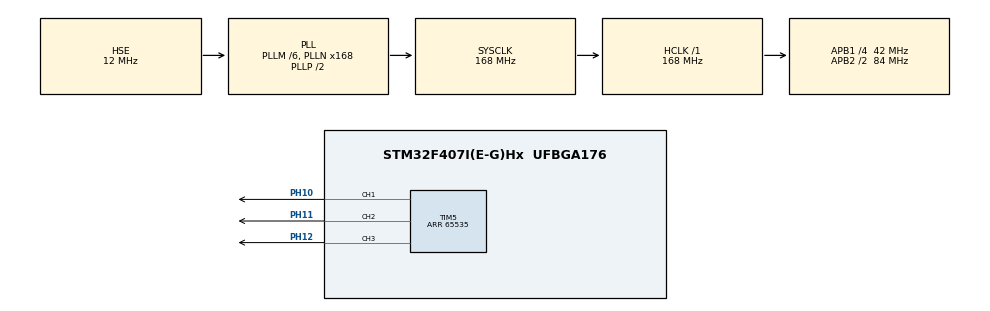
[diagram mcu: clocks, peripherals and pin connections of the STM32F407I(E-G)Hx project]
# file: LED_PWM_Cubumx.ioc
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Mcu.Family=STM32F4
Mcu.Name=STM32F407I(E-G)Hx
Mcu.Package=UFBGA176
NVIC.PriorityGroup=NVIC_PRIORITYGROUP_4
PA13.Mode=Serial_Wire
PA13.Signal=SYS_JTMS-SWDIO
PA14.Mode=Serial_Wire
PA14.Signal=SYS_JTCK-SWCLK
PH0-OSC_IN.Mode=HSE-External-Oscillator
PH0-OSC_IN.Signal=RCC_OSC_IN
PH1-OSC_OUT.Mode=HSE-External-Oscillator
PH1-OSC_OUT.Signal=RCC_OSC_OUT
PH10.Signal=S_TIM5_CH1
PH11.Signal=S_TIM5_CH2
PH12.Signal=S_TIM5_CH3
ProjectManager.HeapSize=0x200
ProjectManager.StackSize=0x400
ProjectManager.TargetToolchain=MDK-ARM V5.32
RCC.48MHZClocksFreq_Value=84000000
RCC.AHBFreq_Value=168000000
RCC.APB1CLKDivider=RCC_HCLK_DIV4
RCC.APB1Freq_Value=42000000
RCC.APB1TimFreq_Value=84000000
RCC.APB2CLKDivider=RCC_HCLK_DIV2
RCC.APB2Freq_Value=84000000
RCC.APB2TimFreq_Value=168000000
RCC.CortexFreq_Value=168000000
RCC.HCLKFreq_Value=168000000
RCC.HSE_VALUE=12000000
RCC.HSI_VALUE=16000000
RCC.LSE_VALUE=32768
RCC.PLLM=6
RCC.PLLN=168
RCC.PLLSourceVirtual=RCC_PLLSOURCE_HSE
RCC.SYSCLKFreq_VALUE=168000000
RCC.SYSCLKSource=RCC_SYSCLKSOURCE_PLLCLK
RCC.VCOOutputFreq_Value=336000000
SH.S_TIM5_CH1.0=TIM5_CH1,PWM Generation1 CH1
SH.S_TIM5_CH2.0=TIM5_CH2,PWM Generation2 CH2
SH.S_TIM5_CH3.0=TIM5_CH3,PWM Generation3 CH3
TIM5.Channel-PWM\ Generation1\ CH1=TIM_CHANNEL_1
TIM5.Channel-PWM\ Generation2\ CH2=TIM_CHANNEL_2
TIM5.Channel-PWM\ Generation3\ CH3=TIM_CHANNEL_3
TIM5.Period=65535
TIM5.Pulse-PWM\ Generation1\ CH1=10000
TIM5.Pulse-PWM\ Generation2\ CH2=10000
VP_TIM5_VS_ClockSourceINT.Mode=Internal
board=custom

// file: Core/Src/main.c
/* USER CODE BEGIN Header */
/**
  ******************************************************************************
  * @file           : main.c
  * @brief          : Main program body
  ******************************************************************************
  * @attention
  *
  * Copyright (c) 2025 STMicroelectronics.
  * All rights reserved.
  *
  * This software is licensed under terms that can be found in the LICENSE file
  * in the root directory of this software component.
  * If no LICENSE file comes with this software, it is provided AS-IS.
  *
  ******************************************************************************
  */
/* USER CODE END Header */
#include "main.h"
#include "tim.h"
#include "gpio.h"

void SystemClock_Config(void);

/* USER CODE BEGIN 0 */
	void aRGB_LED_SHOW(uint32_t aRGB);
/* USER CODE END 0 */

int main(void)
{

  /* USER CODE BEGIN 1 */
	uint32_t colors[] = {
    0xFFFF0000, // 红
    0xFFFFFF00, // 黄
    0xFF00FF00, // 绿
    0xFF00FFFF, // 青
    0xFF0000FF, // 蓝
    0xFFFF00FF  // 紫
	};
  /* USER CODE END 1 */

  /* MCU Configuration--------------------------------------------------------*/

  /* Reset of all peripherals, Initializes the Flash interface and the Systick. */
  HAL_Init();

  /* Configure the system clock */
  SystemClock_Config();

  /* Initialize all configured peripherals */
  MX_GPIO_Init();
  MX_TIM5_Init();
  /* USER CODE BEGIN 2 */
	HAL_TIM_Base_Start(&htim5);
  /* USER CODE END 2 */

  /* Infinite loop */
  while (1)
  {

    /* USER CODE BEGIN 3 */
//		aRGB_LED_SHOW(0xFF0000FF); // 蓝色
//    HAL_Delay(1000);
//    aRGB_LED_SHOW(0xFF00FF00); // 绿色
//    HAL_Delay(1000);
//    aRGB_LED_SHOW(0xFFFF0000); // 红色
//    HAL_Delay(1000);
//    aRGB_LED_SHOW(0xFFFFFFFF); // 白色
//    HAL_Delay(1000);
			for (int c = 0; c < sizeof(colors)/sizeof(colors[0]); ++c)
			{

					aRGB_LED_SHOW( colors[c]);  // 渐亮

					for (int i = 255; i > 0; --i)
					{
							aRGB_LED_SHOW((i << 24) | colors[c]);  // 渐暗
							HAL_Delay(5);
					}
			}
		}
  /* USER CODE END 3 */
}

void SystemClock_Config(void)
{
  RCC_OscInitTypeDef RCC_OscInitStruct = {0};
  RCC_ClkInitTypeDef RCC_ClkInitStruct = {0};

  /** Configure the main internal regulator output voltage
  */
  __HAL_RCC_PWR_CLK_ENABLE();
  __HAL_PWR_VOLTAGESCALING_CONFIG(PWR_REGULATOR_VOLTAGE_SCALE1);

  /** Initializes the RCC Oscillators according to the specified parameters
  * in the RCC_OscInitTypeDef structure.
  */
  RCC_OscInitStruct.OscillatorType = RCC_OSCILLATORTYPE_HSE;
  RCC_OscInitStruct.HSEState = RCC_HSE_ON;
  RCC_OscInitStruct.PLL.PLLState = RCC_PLL_ON;
  RCC_OscInitStruct.PLL.PLLSource = RCC_PLLSOURCE_HSE;
  RCC_OscInitStruct.PLL.PLLM = 6;
  RCC_OscInitStruct.PLL.PLLN = 168;
  RCC_OscInitStruct.PLL.PLLP = RCC_PLLP_DIV2;
  RCC_OscInitStruct.PLL.PLLQ = 4;
  if (HAL_RCC_OscConfig(&RCC_OscInitStruct) != HAL_OK)
  {
    Error_Handler();
  }

  /** Initializes the CPU, AHB and APB buses clocks
  */
  RCC_ClkInitStruct.ClockType = RCC_CLOCKTYPE_HCLK|RCC_CLOCKTYPE_SYSCLK
                              |RCC_CLOCKTYPE_PCLK1|RCC_CLOCKTYPE_PCLK2;
  RCC_ClkInitStruct.SYSCLKSource = RCC_SYSCLKSOURCE_PLLCLK;
  RCC_ClkInitStruct.AHBCLKDivider = RCC_SYSCLK_DIV1;
  RCC_ClkInitStruct.APB1CLKDivider = RCC_HCLK_DIV4;
  RCC_ClkInitStruct.APB2CLKDivider = RCC_HCLK_DIV2;

  if (HAL_RCC_ClockConfig(&RCC_ClkInitStruct, FLASH_LATENCY_5) != HAL_OK)
  {
    Error_Handler();
  }
}

/* USER CODE BEGIN 4 */

void aRGB_LED_SHOW(uint32_t aRGB)
{
    uint8_t alpha = (aRGB >> 24) & 0xFF;
    uint8_t r_raw = (aRGB >> 16) & 0xFF;
    uint8_t g_raw = (aRGB >> 8)  & 0xFF;
    uint8_t b_raw = aRGB & 0xFF;

    uint16_t pwm_max = __HAL_TIM_GET_AUTORELOAD(&htim5);
//设置PWM输出值
    uint16_t red   = r_raw * alpha * pwm_max / (255 * 255);
    uint16_t green = g_raw * alpha * pwm_max / (255 * 255);
    uint16_t blue  = b_raw * alpha * pwm_max / (255 * 255);
//设置通道CCR的值
    __HAL_TIM_SetCompare(&htim5, TIM_CHANNEL_1, red);   // PH10
    __HAL_TIM_SetCompare(&htim5, TIM_CHANNEL_2, green); // PH11
    __HAL_TIM_SetCompare(&htim5, TIM_CHANNEL_3, blue);  // PH12
}

/* USER CODE END 4 */

void Error_Handler(void)
{
  __disable_irq();
  while (1)
  {
  }
}
